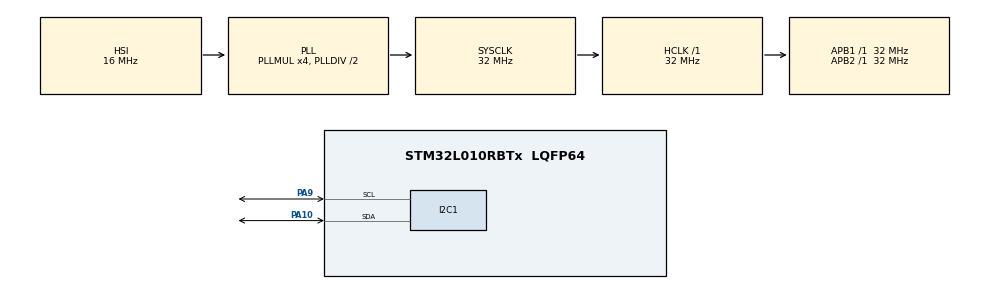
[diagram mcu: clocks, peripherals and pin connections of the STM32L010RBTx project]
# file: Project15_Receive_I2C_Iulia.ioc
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I2C1.Timing=0x00707CBB
Mcu.Family=STM32L0
Mcu.Name=STM32L010RBTx
Mcu.Package=LQFP64
NVIC.I2C1_IRQn=true\:0\:0\:false\:false\:true\:true\:true
PA10.Mode=I2C
PA10.Signal=I2C1_SDA
PA9.Mode=I2C
PA9.Signal=I2C1_SCL
ProjectManager.HeapSize=0x200
ProjectManager.StackSize=0x400
ProjectManager.TargetToolchain=EWARM V8.32
RCC.AHBFreq_Value=32000000
RCC.APB1Freq_Value=32000000
RCC.APB1TimFreq_Value=32000000
RCC.APB2Freq_Value=32000000
RCC.APB2TimFreq_Value=32000000
RCC.HCLKFreq_Value=32000000
RCC.HSE_VALUE=8000000
RCC.HSI16_VALUE=16000000
RCC.HSI48_VALUE=48000000
RCC.HSI_VALUE=16000000
RCC.LSEState=RCC_LSE_ON
RCC.LSE_VALUE=32768
RCC.MSI_VALUE=2097000
RCC.PLLMUL=RCC_PLLMUL_4
RCC.SYSCLKFreq_VALUE=32000000
RCC.SYSCLKSource=RCC_SYSCLKSOURCE_PLLCLK
RCC.VCOOutputFreq_Value=64000000
board=NUCLEO-L010RB

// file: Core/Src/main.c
/* USER CODE BEGIN Header */
/**
  ******************************************************************************
  * @file           : main.c
  * @brief          : Main program body
  ******************************************************************************
  * @attention
  *
  * <h2><center>&copy; Copyright (c) 2021 STMicroelectronics.
  * All rights reserved.</center></h2>
  *
  * This software component is licensed by ST under BSD 3-Clause license,
  * the "License"; You may not use this file except in compliance with the
  * License. You may obtain a copy of the License at:
  *                        opensource.org/licenses/BSD-3-Clause
  *
  ******************************************************************************
  */
/* USER CODE END Header */
#include "main.h"

I2C_HandleTypeDef hi2c1;

/* USER CODE BEGIN PV */
uint8_t rxI2C;
uint8_t Distance;
uint8_t txcI2C[8];
/* USER CODE END PV */

void SystemClock_Config(void);
static void MX_GPIO_Init(void);
static void MX_I2C1_Init(void);

int main(void)
{

  /* MCU Configuration--------------------------------------------------------*/

  /* Reset of all peripherals, Initializes the Flash interface and the Systick. */
  HAL_Init();

  /* Configure the system clock */
  SystemClock_Config();

  /* Initialize all configured peripherals */
  MX_GPIO_Init();
  MX_I2C1_Init();

  /* Infinite loop */
  /* USER CODE BEGIN WHILE */
  while (1)
  {

    HAL_Delay(250);

    HAL_I2C_Slave_Receive(&hi2c1, &rxI2C, 1, HAL_MAX_DELAY);
    HAL_Delay(250);
    if(rxI2C < 5){
     Distance=1;

    }else if(rxI2C >= 5 && rxI2C <10){
     Distance=2;

    }else if(rxI2C >=10){
      Distance=3;

    } else{
      Distance=0;
    }

    HAL_I2C_Master_Transmit(&hi2c1 , 0, &Distance, 1, HAL_MAX_DELAY);
    HAL_Delay(250);

    HAL_I2C_Slave_Receive(&hi2c1, txcI2C, 8, HAL_MAX_DELAY);
    HAL_Delay(250);
    /* USER CODE END WHILE */

  }
}

void SystemClock_Config(void)
{
  RCC_OscInitTypeDef RCC_OscInitStruct = {0};
  RCC_ClkInitTypeDef RCC_ClkInitStruct = {0};
  RCC_PeriphCLKInitTypeDef PeriphClkInit = {0};

  /** Configure the main internal regulator output voltage
  */
  __HAL_PWR_VOLTAGESCALING_CONFIG(PWR_REGULATOR_VOLTAGE_SCALE1);
  /** Initializes the RCC Oscillators according to the specified parameters
  * in the RCC_OscInitTypeDef structure.
  */
  RCC_OscInitStruct.OscillatorType = RCC_OSCILLATORTYPE_HSI;
  RCC_OscInitStruct.HSIState = RCC_HSI_ON;
  RCC_OscInitStruct.HSICalibrationValue = RCC_HSICALIBRATION_DEFAULT;
  RCC_OscInitStruct.PLL.PLLState = RCC_PLL_ON;
  RCC_OscInitStruct.PLL.PLLSource = RCC_PLLSOURCE_HSI;
  RCC_OscInitStruct.PLL.PLLMUL = RCC_PLLMUL_4;
  RCC_OscInitStruct.PLL.PLLDIV = RCC_PLLDIV_2;
  if (HAL_RCC_OscConfig(&RCC_OscInitStruct) != HAL_OK)
  {
    Error_Handler();
  }
  /** Initializes the CPU, AHB and APB buses clocks
  */
  RCC_ClkInitStruct.ClockType = RCC_CLOCKTYPE_HCLK|RCC_CLOCKTYPE_SYSCLK
                              |RCC_CLOCKTYPE_PCLK1|RCC_CLOCKTYPE_PCLK2;
  RCC_ClkInitStruct.SYSCLKSource = RCC_SYSCLKSOURCE_PLLCLK;
  RCC_ClkInitStruct.AHBCLKDivider = RCC_SYSCLK_DIV1;
  RCC_ClkInitStruct.APB1CLKDivider = RCC_HCLK_DIV1;
  RCC_ClkInitStruct.APB2CLKDivider = RCC_HCLK_DIV1;

  if (HAL_RCC_ClockConfig(&RCC_ClkInitStruct, FLASH_LATENCY_1) != HAL_OK)
  {
    Error_Handler();
  }
  PeriphClkInit.PeriphClockSelection = RCC_PERIPHCLK_I2C1;
  PeriphClkInit.I2c1ClockSelection = RCC_I2C1CLKSOURCE_PCLK1;
  if (HAL_RCCEx_PeriphCLKConfig(&PeriphClkInit) != HAL_OK)
  {
    Error_Handler();
  }
}

static void MX_I2C1_Init(void)
{

  hi2c1.Instance = I2C1;
  hi2c1.Init.Timing = 0x00707CBB;
  hi2c1.Init.OwnAddress1 = 0;
  hi2c1.Init.AddressingMode = I2C_ADDRESSINGMODE_7BIT;
  hi2c1.Init.DualAddressMode = I2C_DUALADDRESS_DISABLE;
  hi2c1.Init.OwnAddress2 = 0;
  hi2c1.Init.OwnAddress2Masks = I2C_OA2_NOMASK;
  hi2c1.Init.GeneralCallMode = I2C_GENERALCALL_DISABLE;
  hi2c1.Init.NoStretchMode = I2C_NOSTRETCH_DISABLE;
  if (HAL_I2C_Init(&hi2c1) != HAL_OK)
  {
    Error_Handler();
  }
  /** Configure Analogue filter
  */
  if (HAL_I2CEx_ConfigAnalogFilter(&hi2c1, I2C_ANALOGFILTER_ENABLE) != HAL_OK)
  {
    Error_Handler();
  }
  /** Configure Digital filter
  */
  if (HAL_I2CEx_ConfigDigitalFilter(&hi2c1, 0) != HAL_OK)
  {
    Error_Handler();
  }

}

static void MX_GPIO_Init(void)
{

  /* GPIO Ports Clock Enable */
  __HAL_RCC_GPIOA_CLK_ENABLE();

}

void Error_Handler(void)
{
  __disable_irq();
  while (1)
  {
  }
}

/************************ (C) COPYRIGHT STMicroelectronics *****END OF FILE****/
